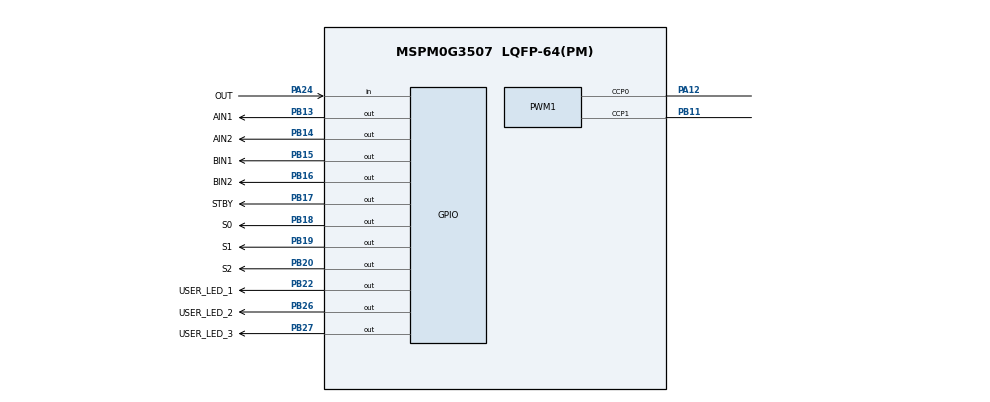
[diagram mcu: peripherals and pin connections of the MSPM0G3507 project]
//@cliArgs --device "MSPM0G350X" --package "LQFP-64(PM)" --part "Default"
//@v2CliArgs --device "MSPM0G3507" --package "LQFP-64(PM)"
// @cliArgs --board /ti/boards/LP_MSPM0G3507 --rtos nortos

/**
 * Import the modules used in this configuration.
 */
const GPIO   = scripting.addModule("/ti/driverlib/GPIO", {}, false);
const GPIO1  = GPIO.addInstance();
const GPIO2  = GPIO.addInstance();
const GPIO3  = GPIO.addInstance();
const PWM    = scripting.addModule("/ti/driverlib/PWM", {}, false);
const PWM1   = PWM.addInstance();
const SYSCTL = scripting.addModule("/ti/driverlib/SYSCTL");

/**
 * Write custom configuration values to the imported modules.
 */
GPIO1.$name                         = "GPIO_LEDS";
GPIO1.associatedPins.create(3);
GPIO1.associatedPins[0].$name       = "USER_LED_1";
GPIO1.associatedPins[0].pin.$assign  = "PB22";
GPIO1.associatedPins[1].$name       = "USER_LED_2";
GPIO1.associatedPins[1].pin.$assign  = "PB26";
GPIO1.associatedPins[2].$name       = "USER_LED_3";
GPIO1.associatedPins[2].pin.$assign  = "PB27";

GPIO2.$name                          = "GPIO_MOTOR";
GPIO2.associatedPins.create(5);
GPIO2.associatedPins[0].$name        = "AIN1";
GPIO2.associatedPins[0].pin.$assign  = "PB13";
GPIO2.associatedPins[1].$name        = "AIN2";
GPIO2.associatedPins[1].pin.$assign  = "PB14";
GPIO2.associatedPins[2].$name        = "BIN1";
GPIO2.associatedPins[2].pin.$assign  = "PB15";
GPIO2.associatedPins[3].$name        = "BIN2";
GPIO2.associatedPins[3].pin.$assign  = "PB16";
GPIO2.associatedPins[4].$name        = "STBY";
GPIO2.associatedPins[4].pin.$assign  = "PB17";

GPIO3.$name                          = "GPIO_SENSOR";
GPIO3.associatedPins.create(4);
GPIO3.associatedPins[0].$name        = "S0";
GPIO3.associatedPins[0].pin.$assign  = "PB18";
GPIO3.associatedPins[1].$name        = "S1";
GPIO3.associatedPins[1].pin.$assign  = "PB19";
GPIO3.associatedPins[2].$name        = "S2";
GPIO3.associatedPins[2].pin.$assign  = "PB20";
GPIO3.associatedPins[3].$name        = "OUT";
GPIO3.associatedPins[3].direction    = "INPUT";
GPIO3.associatedPins[3].pin.$assign  = "PA24";

const Board = scripting.addModule("/ti/driverlib/Board", {}, false);

SYSCTL.forceDefaultClkConfig = true;
SYSCTL.clockTreeEn  = true;

PWM1.$name                      = "PWM_MOTOR";
PWM1.timerCount                 = 1600;
PWM1.ccIndex                    = [0,1];
PWM1.peripheral.$assign         = "TIMG0";
PWM1.pwmMode                    = "EDGE_ALIGN_UP";
PWM1.peripheral.ccp0Pin.$assign = "PA12";
PWM1.peripheral.ccp1Pin.$assign = "PB11";
PWM1.PWM_CHANNEL_0.$name        = "ti_driverlib_pwm_PWMTimerCC0";
PWM1.PWM_CHANNEL_1.$name        = "ti_driverlib_pwm_PWMTimerCC1";
